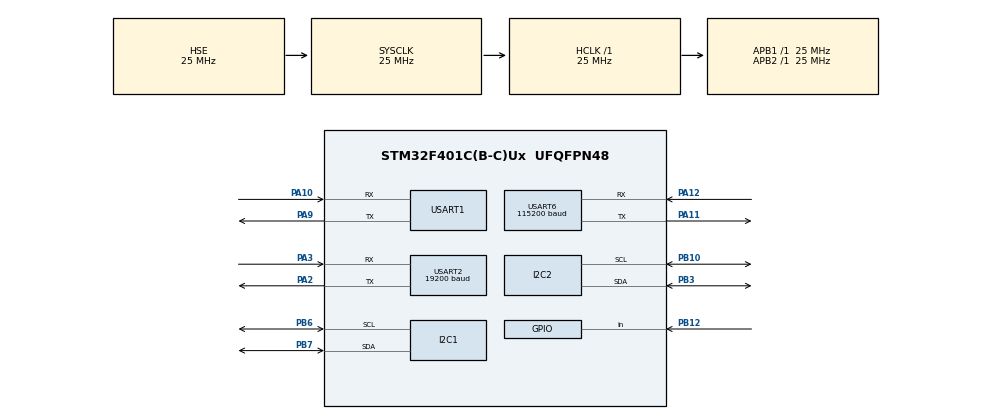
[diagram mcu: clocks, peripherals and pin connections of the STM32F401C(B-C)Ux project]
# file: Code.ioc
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Dma.Request0=USART2_RX
Dma.Request1=USART2_TX
Dma.Request2=USART6_RX
Dma.USART2_RX.0.Direction=DMA_PERIPH_TO_MEMORY
Dma.USART2_RX.0.FIFOMode=DMA_FIFOMODE_DISABLE
Dma.USART2_RX.0.Instance=DMA1_Stream5
Dma.USART2_RX.0.MemDataAlignment=DMA_MDATAALIGN_BYTE
Dma.USART2_RX.0.MemInc=DMA_MINC_ENABLE
Dma.USART2_RX.0.Mode=DMA_CIRCULAR
Dma.USART2_RX.0.PeriphDataAlignment=DMA_PDATAALIGN_BYTE
Dma.USART2_RX.0.PeriphInc=DMA_PINC_DISABLE
Dma.USART2_RX.0.Priority=DMA_PRIORITY_LOW
Dma.USART2_TX.1.Direction=DMA_MEMORY_TO_PERIPH
Dma.USART2_TX.1.FIFOMode=DMA_FIFOMODE_DISABLE
Dma.USART2_TX.1.Instance=DMA1_Stream6
Dma.USART2_TX.1.MemDataAlignment=DMA_MDATAALIGN_BYTE
Dma.USART2_TX.1.MemInc=DMA_MINC_ENABLE
Dma.USART2_TX.1.Mode=DMA_NORMAL
Dma.USART2_TX.1.PeriphDataAlignment=DMA_PDATAALIGN_BYTE
Dma.USART2_TX.1.PeriphInc=DMA_PINC_DISABLE
Dma.USART2_TX.1.Priority=DMA_PRIORITY_MEDIUM
Dma.USART6_RX.2.Direction=DMA_PERIPH_TO_MEMORY
Dma.USART6_RX.2.FIFOMode=DMA_FIFOMODE_DISABLE
Dma.USART6_RX.2.Instance=DMA2_Stream1
Dma.USART6_RX.2.MemDataAlignment=DMA_MDATAALIGN_BYTE
Dma.USART6_RX.2.MemInc=DMA_MINC_ENABLE
Dma.USART6_RX.2.Mode=DMA_CIRCULAR
Dma.USART6_RX.2.PeriphDataAlignment=DMA_PDATAALIGN_BYTE
Dma.USART6_RX.2.PeriphInc=DMA_PINC_DISABLE
Dma.USART6_RX.2.Priority=DMA_PRIORITY_LOW
Mcu.Family=STM32F4
Mcu.Name=STM32F401C(B-C)Ux
Mcu.Package=UFQFPN48
NVIC.DMA1_Stream5_IRQn=true\:0\:0\:false\:false\:true\:false\:true\:true
NVIC.DMA1_Stream6_IRQn=true\:0\:0\:false\:false\:true\:false\:true\:true
NVIC.DMA2_Stream1_IRQn=true\:0\:0\:false\:false\:true\:false\:true\:true
NVIC.PriorityGroup=NVIC_PRIORITYGROUP_4
NVIC.TIM1_BRK_TIM9_IRQn=true\:0\:0\:false\:false\:true\:true\:true\:true
NVIC.USART6_IRQn=true\:0\:0\:false\:false\:true\:true\:true\:true
PA10.Mode=Asynchronous
PA10.Signal=USART1_RX
PA11.Mode=Asynchronous
PA11.Signal=USART6_TX
PA12.Mode=Asynchronous
PA12.Signal=USART6_RX
PA13.Mode=Serial_Wire
PA13.Signal=SYS_JTMS-SWDIO
PA14.Mode=Serial_Wire
PA14.Signal=SYS_JTCK-SWCLK
PA2.Mode=Asynchronous
PA2.Signal=USART2_TX
PA3.Mode=Asynchronous
PA3.Signal=USART2_RX
PA9.Mode=Asynchronous
PA9.Signal=USART1_TX
PB10.Mode=I2C
PB10.Signal=I2C2_SCL
PB12.GPIO_PuPd=GPIO_PULLUP
PB12.Signal=GPIO_Input
PB3.Mode=I2C
PB3.Signal=I2C2_SDA
PB6.Mode=I2C
PB6.Signal=I2C1_SCL
PB7.Mode=I2C
PB7.Signal=I2C1_SDA
PH0\ -\ OSC_IN.Mode=HSE-External-Oscillator
PH0\ -\ OSC_IN.Signal=RCC_OSC_IN
PH1\ -\ OSC_OUT.Mode=HSE-External-Oscillator
PH1\ -\ OSC_OUT.Signal=RCC_OSC_OUT
ProjectManager.HeapSize=0x200
ProjectManager.StackSize=0x400
ProjectManager.TargetToolchain=MDK-ARM V5.32
RCC.48MHZClocksFreq_Value=42000000
RCC.AHBFreq_Value=25000000
RCC.APB1Freq_Value=25000000
RCC.APB1TimFreq_Value=25000000
RCC.APB2Freq_Value=25000000
RCC.APB2TimFreq_Value=25000000
RCC.CortexFreq_Value=25000000
RCC.HCLKFreq_Value=25000000
RCC.HSE_VALUE=25000000
RCC.HSI_VALUE=16000000
RCC.LSE_VALUE=32768
RCC.PLLM=25
RCC.PLLN=168
RCC.PLLSourceVirtual=RCC_PLLSOURCE_HSE
RCC.RCC_RTC_Clock_Source=RCC_RTCCLKSOURCE_LSE
RCC.RCC_RTC_Clock_SourceVirtual=RCC_RTCCLKSOURCE_LSE
RCC.SYSCLKFreq_VALUE=25000000
RCC.SYSCLKSource=RCC_SYSCLKSOURCE_HSE
RCC.VCOOutputFreq_Value=168000000
TIM9.AutoReloadPreload=TIM_AUTORELOAD_PRELOAD_ENABLE
TIM9.Prescaler=84-1
USART1.VirtualMode=VM_ASYNC
USART2.BaudRate=19200
USART2.OverSampling=UART_OVERSAMPLING_8
USART2.VirtualMode=VM_ASYNC
USART6.BaudRate=115200
USART6.VirtualMode=VM_ASYNC
VP_TIM9_VS_ClockSourceINT.Mode=Internal
board=custom

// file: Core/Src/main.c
/* USER CODE BEGIN Header */
/**
  ******************************************************************************
  * @file           : main.c
  * @brief          : Main program body
  ******************************************************************************
  * @attention
  *
  * Copyright (c) 2023 STMicroelectronics.
  * All rights reserved.
  *
  * This software is licensed under terms that can be found in the LICENSE file
  * in the root directory of this software component.
  * If no LICENSE file comes with this software, it is provided AS-IS.
  *
  ******************************************************************************
  */
/* USER CODE END Header */
#include "main.h"
#include "dma.h"
#include "i2c.h"
#include "tim.h"
#include "usart.h"
#include "gpio.h"

/* USER CODE BEGIN Includes */
#include "statemachine.h"
/* USER CODE END Includes */

void SystemClock_Config(void);

int main(void)
{
  /* USER CODE BEGIN 1 */
  //while (1);
  /* USER CODE END 1 */

  /* MCU Configuration--------------------------------------------------------*/

  /* Reset of all peripherals, Initializes the Flash interface and the Systick. */
  HAL_Init();

  /* Configure the system clock */
  SystemClock_Config();

  /* Initialize all configured peripherals */
  MX_GPIO_Init();
  MX_DMA_Init();
  MX_USART2_UART_Init();
  MX_USART1_UART_Init();
  MX_I2C2_Init();
  MX_TIM9_Init();
  MX_I2C1_Init();
  MX_USART6_UART_Init();

  /* Infinite loop */
  while (1)
  {

    /* USER CODE BEGIN 3 */
		if(HAL_GPIO_ReadPin(GPIOB,GPIO_PIN_12) == RESET)
		{
			HAL_Delay(200);
			if(HAL_GPIO_ReadPin(GPIOB,GPIO_PIN_12) == RESET)
			{
				while(HAL_GPIO_ReadPin(GPIOB,GPIO_PIN_12) == RESET);
				printf("start\r\n");
				loop();
			}
		}
  }
  /* USER CODE END 3 */
}

void SystemClock_Config(void)
{
  RCC_OscInitTypeDef RCC_OscInitStruct = {0};
  RCC_ClkInitTypeDef RCC_ClkInitStruct = {0};

  /** Configure the main internal regulator output voltage
  */
  __HAL_RCC_PWR_CLK_ENABLE();
  __HAL_PWR_VOLTAGESCALING_CONFIG(PWR_REGULATOR_VOLTAGE_SCALE2);

  /** Initializes the RCC Oscillators according to the specified parameters
  * in the RCC_OscInitTypeDef structure.
  */
  RCC_OscInitStruct.OscillatorType = RCC_OSCILLATORTYPE_HSE;
  RCC_OscInitStruct.HSEState = RCC_HSE_ON;
  RCC_OscInitStruct.PLL.PLLState = RCC_PLL_NONE;
  if (HAL_RCC_OscConfig(&RCC_OscInitStruct) != HAL_OK)
  {
    Error_Handler();
  }

  /** Initializes the CPU, AHB and APB buses clocks
  */
  RCC_ClkInitStruct.ClockType = RCC_CLOCKTYPE_HCLK|RCC_CLOCKTYPE_SYSCLK
                              |RCC_CLOCKTYPE_PCLK1|RCC_CLOCKTYPE_PCLK2;
  RCC_ClkInitStruct.SYSCLKSource = RCC_SYSCLKSOURCE_HSE;
  RCC_ClkInitStruct.AHBCLKDivider = RCC_SYSCLK_DIV1;
  RCC_ClkInitStruct.APB1CLKDivider = RCC_HCLK_DIV1;
  RCC_ClkInitStruct.APB2CLKDivider = RCC_HCLK_DIV1;

  if (HAL_RCC_ClockConfig(&RCC_ClkInitStruct, FLASH_LATENCY_0) != HAL_OK)
  {
    Error_Handler();
  }
}

void Error_Handler(void)
{
  __disable_irq();
  while (1)
  {
  }
}
